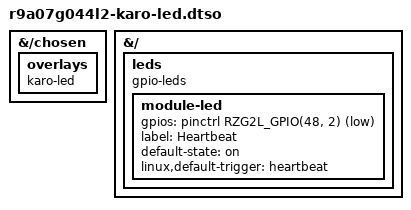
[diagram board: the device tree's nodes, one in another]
// SPDX-License-Identifier: (GPL-2.0-only OR BSD-3-Clause)
/*
 * Copyright (C) 2023 Markus Bauer <MB@karo-electronics.com>
 */
/dts-v1/;
/plugin/;

#include <dt-bindings/gpio/gpio.h>
#include <dt-bindings/pinctrl/rzg2l-pinctrl.h>

&{/chosen} {
	overlays {
		karo-led;
	};
};

&{/} {
	leds {
		compatible = "gpio-leds";

		module-led {
			gpios = <&pinctrl RZG2L_GPIO(48, 2) GPIO_ACTIVE_LOW>;
			label = "Heartbeat";
			default-state = "on";
			linux,default-trigger = "heartbeat";
		};
	};
};
